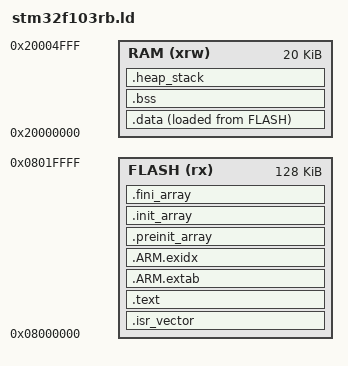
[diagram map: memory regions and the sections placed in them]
ENTRY(Reset_Handler)
MEMORY {
  FLASH (rx) : ORIGIN = 0x08000000, LENGTH = 128K
  RAM (xrw) : ORIGIN = 0x20000000, LENGTH = 20K
}
_estack = ORIGIN(RAM) + LENGTH(RAM);
SECTIONS {
  .isr_vector : { . = ALIGN(4); KEEP(*(.isr_vector)) } > FLASH
  .text : { *(.text*) *(.rodata*) KEEP(*(.init)) KEEP(*(.fini)) . = ALIGN(4); _etext = .; } > FLASH
  .ARM.extab : { *(.ARM.extab*) } > FLASH
  .ARM.exidx : { __exidx_start = .; *(.ARM.exidx*) __exidx_end = .; } > FLASH
  .preinit_array : { PROVIDE_HIDDEN(__preinit_array_start = .); KEEP(*(.preinit_array*)) PROVIDE_HIDDEN(__preinit_array_end = .); } > FLASH
  .init_array : { PROVIDE_HIDDEN(__init_array_start = .); KEEP(*(SORT(.init_array.*))) KEEP(*(.init_array*)) PROVIDE_HIDDEN(__init_array_end = .); } > FLASH
  .fini_array : { PROVIDE_HIDDEN(__fini_array_start = .); KEEP(*(SORT(.fini_array.*))) KEEP(*(.fini_array*)) PROVIDE_HIDDEN(__fini_array_end = .); } > FLASH
  _sidata = LOADADDR(.data);
  .data : { . = ALIGN(4); _sdata = .; *(.data*) . = ALIGN(4); _edata = .; } > RAM AT > FLASH
  .bss (NOLOAD) : { . = ALIGN(4); _sbss = .; *(.bss*) *(COMMON) . = ALIGN(4); _ebss = .; } > RAM
  .heap_stack (NOLOAD) : { . = ALIGN(8); end = .; _end = .; . += 0x100; . += 0x1000; } > RAM
  /DISCARD/ : { *(.note.GNU-stack) }
}
ASSERT(_ebss + 0x1100 <= _estack, "RAM overflow: keep 4KiB stack and 256B libc heap reserve")
